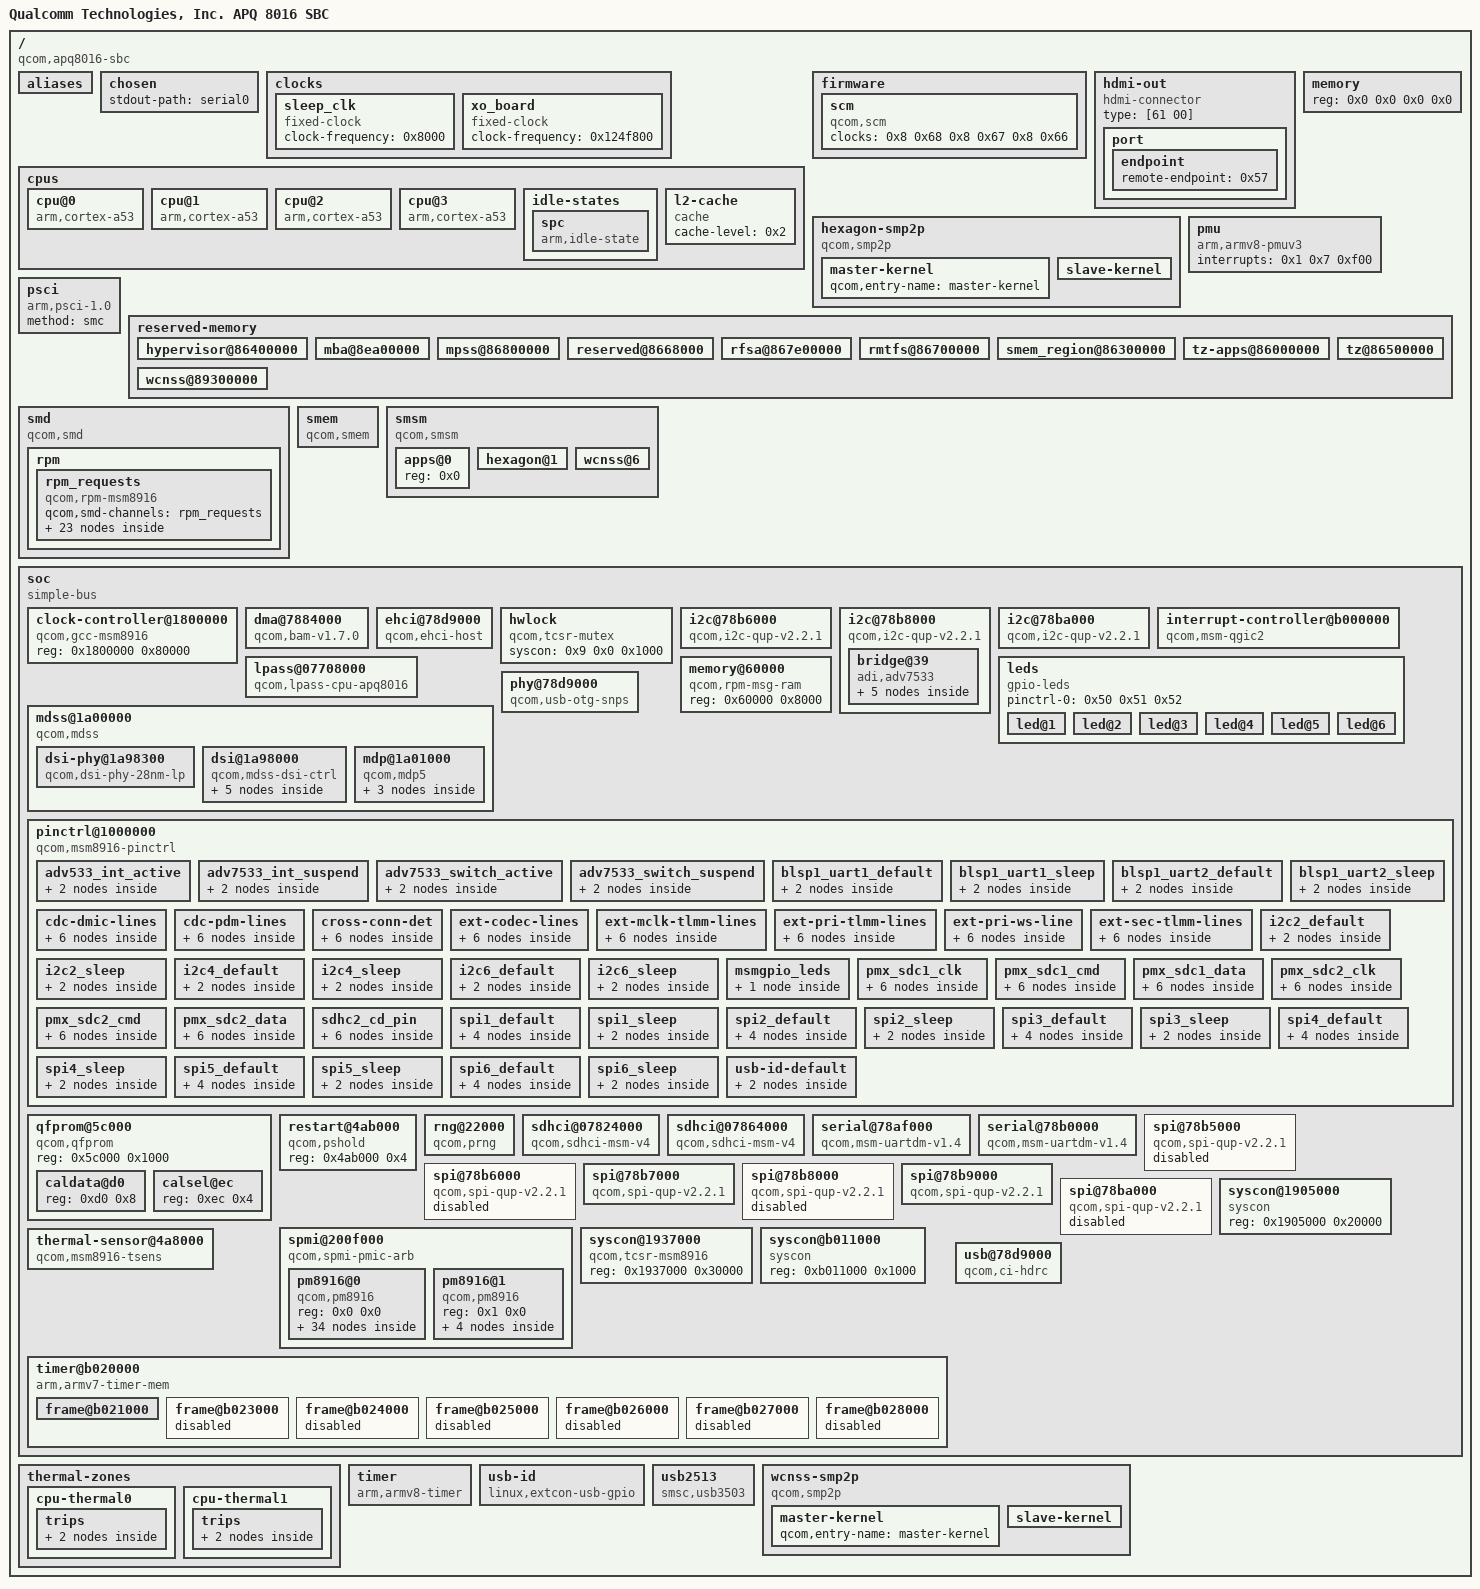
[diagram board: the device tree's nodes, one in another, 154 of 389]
/dts-v1/;

/ {
	#address-cells = <0x2>;
	#size-cells = <0x2>;
	compatible = "qcom,apq8016-sbc", "qcom,apq8016", "qcom,sbc";
	interrupt-parent = <0x1>;
	model = "Qualcomm Technologies, Inc. APQ 8016 SBC";

	__symbols__ {
		CPU0 = "/cpus/cpu@0";
		CPU1 = "/cpus/cpu@1";
		CPU2 = "/cpus/cpu@2";
		CPU3 = "/cpus/cpu@3";
		CPU_SPC = "/cpus/idle-states/spc";
		L2_0 = "/cpus/l2-cache";
		adv7533_in = "/soc/i2c@78b8000/bridge@39/ports/port@0/endpoint";
		adv7533_int_active = "/soc/pinctrl@1000000/adv533_int_active";
		adv7533_int_suspend = "/soc/pinctrl@1000000/adv7533_int_suspend";
		adv7533_out = "/soc/i2c@78b8000/bridge@39/ports/port@1/endpoint";
		adv7533_switch_active = "/soc/pinctrl@1000000/adv7533_switch_active";
		adv7533_switch_suspend = "/soc/pinctrl@1000000/adv7533_switch_suspend";
		adv_bridge = "/soc/i2c@78b8000/bridge@39";
		apcs = "/soc/syscon@b011000";
		apps_smsm = "/smsm/apps@0";
		blsp1_uart1 = "/soc/serial@78af000";
		blsp1_uart1_default = "/soc/pinctrl@1000000/blsp1_uart1_default";
		blsp1_uart1_sleep = "/soc/pinctrl@1000000/blsp1_uart1_sleep";
		blsp1_uart2 = "/soc/serial@78b0000";
		blsp1_uart2_default = "/soc/pinctrl@1000000/blsp1_uart2_default";
		blsp1_uart2_sleep = "/soc/pinctrl@1000000/blsp1_uart2_sleep";
		blsp_dma = "/soc/dma@7884000";
		blsp_i2c2 = "/soc/i2c@78b6000";
		blsp_i2c4 = "/soc/i2c@78b8000";
		blsp_i2c6 = "/soc/i2c@78ba000";
		blsp_spi1 = "/soc/spi@78b5000";
		blsp_spi2 = "/soc/spi@78b6000";
		blsp_spi3 = "/soc/spi@78b7000";
		blsp_spi4 = "/soc/spi@78b8000";
		blsp_spi5 = "/soc/spi@78b9000";
		blsp_spi6 = "/soc/spi@78ba000";
		cdc_dmic_lines_act = "/soc/pinctrl@1000000/cdc-dmic-lines/dmic_lines_on";
		cdc_dmic_lines_sus = "/soc/pinctrl@1000000/cdc-dmic-lines/dmic_lines_off";
		cdc_pdm_lines_act = "/soc/pinctrl@1000000/cdc-pdm-lines/pdm_lines_on";
		cdc_pdm_lines_sus = "/soc/pinctrl@1000000/cdc-pdm-lines/pdm_lines_off";
		cpu_alert0 = "/thermal-zones/cpu-thermal0/trips/trip0";
		cpu_alert1 = "/thermal-zones/cpu-thermal1/trips/trip0";
		cpu_crit0 = "/thermal-zones/cpu-thermal0/trips/trip1";
		cpu_crit1 = "/thermal-zones/cpu-thermal1/trips/trip1";
		cross_conn_det_act = "/soc/pinctrl@1000000/cross-conn-det/lines_on";
		cross_conn_det_sus = "/soc/pinctrl@1000000/cross-conn-det/lines_off";
		dsi0 = "/soc/mdss@1a00000/dsi@1a98000";
		dsi0_in = "/soc/mdss@1a00000/dsi@1a98000/ports/port@0/endpoint";
		dsi0_out = "/soc/mdss@1a00000/dsi@1a98000/ports/port@1/endpoint";
		dsi_phy0 = "/soc/mdss@1a00000/dsi-phy@1a98300";
		ext_codec_lines_act = "/soc/pinctrl@1000000/ext-codec-lines/lines_on";
		ext_codec_lines_sus = "/soc/pinctrl@1000000/ext-codec-lines/lines_off";
		ext_mclk_tlmm_lines_act = "/soc/pinctrl@1000000/ext-mclk-tlmm-lines/mclk_lines_on";
		ext_mclk_tlmm_lines_sus = "/soc/pinctrl@1000000/ext-mclk-tlmm-lines/mclk_lines_off";
		ext_pri_tlmm_lines_act = "/soc/pinctrl@1000000/ext-pri-tlmm-lines/ext_pa_on";
		ext_pri_tlmm_lines_sus = "/soc/pinctrl@1000000/ext-pri-tlmm-lines/ext_pa_off";
		ext_pri_ws_act = "/soc/pinctrl@1000000/ext-pri-ws-line/ext_pa_on";
		ext_pri_ws_sus = "/soc/pinctrl@1000000/ext-pri-ws-line/ext_pa_off";
		ext_sec_tlmm_lines_act = "/soc/pinctrl@1000000/ext-sec-tlmm-lines/tlmm_lines_on";
		ext_sec_tlmm_lines_sus = "/soc/pinctrl@1000000/ext-sec-tlmm-lines/tlmm_lines_off";
		gcc = "/soc/clock-controller@1800000";
		hdmi_con = "/hdmi-out/port/endpoint";
		hexagon_smp2p_in = "/hexagon-smp2p/slave-kernel";
		hexagon_smp2p_out = "/hexagon-smp2p/master-kernel";
		hexagon_smsm = "/smsm/hexagon@1";
		i2c2_default = "/soc/pinctrl@1000000/i2c2_default";
		i2c2_sleep = "/soc/pinctrl@1000000/i2c2_sleep";
		i2c4_default = "/soc/pinctrl@1000000/i2c4_default";
		i2c4_sleep = "/soc/pinctrl@1000000/i2c4_sleep";
		i2c6_default = "/soc/pinctrl@1000000/i2c6_default";
		i2c6_sleep = "/soc/pinctrl@1000000/i2c6_sleep";
		intc = "/soc/interrupt-controller@b000000";
		lpass = "/soc/lpass@07708000";
		mba_mem = "/reserved-memory/mba@8ea00000";
		mdp = "/soc/mdss@1a00000/mdp@1a01000";
		mdp5_intf1_out = "/soc/mdss@1a00000/mdp@1a01000/ports/port@0/endpoint";
		mdss = "/soc/mdss@1a00000";
		msmgpio = "/soc/pinctrl@1000000";
		msmgpio_leds = "/soc/pinctrl@1000000/msmgpio_leds";
		pm8916_0 = "/soc/spmi@200f000/pm8916@0";
		pm8916_1 = "/soc/spmi@200f000/pm8916@1";
		pm8916_adc_tm = "/soc/spmi@200f000/pm8916@0/vadc@3400";
		pm8916_bms = "/soc/spmi@200f000/pm8916@0/qcom,vmbms";
		pm8916_chg = "/soc/spmi@200f000/pm8916@0/qcom,charger";
		pm8916_coincell = "/soc/spmi@200f000/pm8916@0/qcom,coincell@2800";
		pm8916_gpios = "/soc/spmi@200f000/pm8916@0/pinctrl@c000";
		pm8916_gpios_leds = "/soc/spmi@200f000/pm8916@0/pinctrl@c000/pm8916_gpios_leds";
		pm8916_l1 = "/smd/rpm/rpm_requests/pm8916-regulators/l1";
		pm8916_l10 = "/smd/rpm/rpm_requests/pm8916-regulators/l10";
		pm8916_l11 = "/smd/rpm/rpm_requests/pm8916-regulators/l11";
		pm8916_l12 = "/smd/rpm/rpm_requests/pm8916-regulators/l12";
		pm8916_l13 = "/smd/rpm/rpm_requests/pm8916-regulators/l13";
		pm8916_l14 = "/smd/rpm/rpm_requests/pm8916-regulators/l14";
		pm8916_l15 = "/smd/rpm/rpm_requests/pm8916-regulators/l15";
		pm8916_l16 = "/smd/rpm/rpm_requests/pm8916-regulators/l16";
		pm8916_l17 = "/smd/rpm/rpm_requests/pm8916-regulators/l17";
		pm8916_l18 = "/smd/rpm/rpm_requests/pm8916-regulators/l18";
		pm8916_l2 = "/smd/rpm/rpm_requests/pm8916-regulators/l2";
		pm8916_l3 = "/smd/rpm/rpm_requests/pm8916-regulators/l3";
		pm8916_l4 = "/smd/rpm/rpm_requests/pm8916-regulators/l4";
		pm8916_l5 = "/smd/rpm/rpm_requests/pm8916-regulators/l5";
		pm8916_l6 = "/smd/rpm/rpm_requests/pm8916-regulators/l6";
		pm8916_l7 = "/smd/rpm/rpm_requests/pm8916-regulators/l7";
		pm8916_l8 = "/smd/rpm/rpm_requests/pm8916-regulators/l8";
		pm8916_l9 = "/smd/rpm/rpm_requests/pm8916-regulators/l9";
		pm8916_leds = "/soc/spmi@200f000/pm8916@0/qcom,leds@a100";
		pm8916_mpps = "/soc/spmi@200f000/pm8916@0/mpps@a000";
		pm8916_mpps_leds = "/soc/spmi@200f000/pm8916@0/mpps@a000/pm8916_mpps_leds";
		pm8916_pon = "/soc/spmi@200f000/pm8916@0/qcom,power-on@800";
		pm8916_pwm = "/soc/spmi@200f000/pm8916@1/qcom,pwms@bc00";
		pm8916_revid = "/soc/spmi@200f000/pm8916@0/qcom,revid@100";
		pm8916_rtc = "/soc/spmi@200f000/pm8916@0/qcom,pm8916_rtc";
		pm8916_s1 = "/smd/rpm/rpm_requests/pm8916-regulators/s1";
		pm8916_s3 = "/smd/rpm/rpm_requests/pm8916-regulators/s3";
		pm8916_s4 = "/smd/rpm/rpm_requests/pm8916-regulators/s4";
		pm8916_tombak_analog = "/soc/spmi@200f000/pm8916@1/msm8x16_wcd_codec@f100";
		pm8916_tombak_dig = "/soc/spmi@200f000/pm8916@1/msm8x16_wcd_codec@f000";
		pm8916_tz = "/soc/spmi@200f000/pm8916@0/qcom,temp-alarm@2400";
		pm8916_vadc = "/soc/spmi@200f000/pm8916@0/vadc@3100";
		pm8916_vib = "/soc/spmi@200f000/pm8916@1/qcom,vibrator@c000";
		qfprom = "/soc/qfprom@5c000";
		rpm_msg_ram = "/soc/memory@60000";
		rpmcc = "/smd/rpm/rpm_requests/qcom,rpmcc";
		scm = "/firmware/scm";
		sdc1_clk_off = "/soc/pinctrl@1000000/pmx_sdc1_clk/clk_off";
		sdc1_clk_on = "/soc/pinctrl@1000000/pmx_sdc1_clk/clk_on";
		sdc1_cmd_off = "/soc/pinctrl@1000000/pmx_sdc1_cmd/cmd_off";
		sdc1_cmd_on = "/soc/pinctrl@1000000/pmx_sdc1_cmd/cmd_on";
		sdc1_data_off = "/soc/pinctrl@1000000/pmx_sdc1_data/data_off";
		sdc1_data_on = "/soc/pinctrl@1000000/pmx_sdc1_data/data_on";
		sdc2_cd_off = "/soc/pinctrl@1000000/sdhc2_cd_pin/cd_off";
		sdc2_cd_on = "/soc/pinctrl@1000000/sdhc2_cd_pin/cd_on";
		sdc2_clk_off = "/soc/pinctrl@1000000/pmx_sdc2_clk/clk_off";
		sdc2_clk_on = "/soc/pinctrl@1000000/pmx_sdc2_clk/clk_on";
		sdc2_cmd_off = "/soc/pinctrl@1000000/pmx_sdc2_cmd/cmd_off";
		sdc2_cmd_on = "/soc/pinctrl@1000000/pmx_sdc2_cmd/cmd_on";
		sdc2_data_off = "/soc/pinctrl@1000000/pmx_sdc2_data/data_off";
		sdc2_data_on = "/soc/pinctrl@1000000/pmx_sdc2_data/data_on";
		sdhc_1 = "/soc/sdhci@07824000";
		sdhc_2 = "/soc/sdhci@07864000";
		sleep_clk = "/clocks/sleep_clk";
		smd_rpm_regulators = "/smd/rpm/rpm_requests/pm8916-regulators";
		smem_mem = "/reserved-memory/smem_region@86300000";
		soc = "/soc";
		spi1_default = "/soc/pinctrl@1000000/spi1_default";
		spi1_sleep = "/soc/pinctrl@1000000/spi1_sleep";
		spi2_default = "/soc/pinctrl@1000000/spi2_default";
		spi2_sleep = "/soc/pinctrl@1000000/spi2_sleep";
		spi3_default = "/soc/pinctrl@1000000/spi3_default";
		spi3_sleep = "/soc/pinctrl@1000000/spi3_sleep";
		spi4_default = "/soc/pinctrl@1000000/spi4_default";
		spi4_sleep = "/soc/pinctrl@1000000/spi4_sleep";
		spi5_default = "/soc/pinctrl@1000000/spi5_default";
		spi5_sleep = "/soc/pinctrl@1000000/spi5_sleep";
		spi6_default = "/soc/pinctrl@1000000/spi6_default";
		spi6_sleep = "/soc/pinctrl@1000000/spi6_sleep";
		spmi_bus = "/soc/spmi@200f000";
		tcsr = "/soc/syscon@1937000";
		tcsr_mutex = "/soc/hwlock";
		tcsr_mutex_regs = "/soc/syscon@1905000";
		tsens = "/soc/thermal-sensor@4a8000";
		tsens_caldata = "/soc/qfprom@5c000/caldata@d0";
		tsens_calsel = "/soc/qfprom@5c000/calsel@ec";
		usb_dev = "/soc/usb@78d9000";
		usb_host = "/soc/ehci@78d9000";
		usb_hub_reset_pm = "/soc/spmi@200f000/pm8916@0/pinctrl@c000/usb_hub_reset_pm";
		usb_id = "/usb-id";
		usb_id_default = "/soc/pinctrl@1000000/usb-id-default";
		usb_otg = "/soc/phy@78d9000";
		usb_sw_sel_pm = "/soc/spmi@200f000/pm8916@0/pinctrl@c000/usb_sw_sel_pm";
		wcnss_smp2p_in = "/wcnss-smp2p/slave-kernel";
		wcnss_smp2p_out = "/wcnss-smp2p/master-kernel";
		wcnss_smsm = "/smsm/wcnss@6";
		xo_board = "/clocks/xo_board";
	};

	aliases {
		i2c0 = "/soc/i2c@78b6000";
		i2c1 = "/soc/i2c@78ba000";
		i2c3 = "/soc/i2c@78b8000";
		sdhc1 = "/soc/sdhci@07824000";
		sdhc2 = "/soc/sdhci@07864000";
		serial0 = "/soc/serial@78b0000";
		serial1 = "/soc/serial@78af000";
		spi0 = "/soc/spi@78b9000";
		spi1 = "/soc/spi@78b7000";
		usid0 = "/soc/spmi@200f000/pm8916@0";
	};

	chosen {
		stdout-path = "serial0";
	};

	clocks {

		sleep_clk {
			#clock-cells = <0x0>;
			clock-frequency = <0x8000>;
			compatible = "fixed-clock";
			phandle = <0x62>;
		};

		xo_board {
			#clock-cells = <0x0>;
			clock-frequency = <0x124f800>;
			compatible = "fixed-clock";
			phandle = <0x61>;
		};
	};

	cpus {
		#address-cells = <0x1>;
		#size-cells = <0x0>;

		cpu@0 {
			compatible = "arm,cortex-a53", "arm,armv8";
			cpu-idle-states = <0x3>;
			device_type = "cpu";
			enable-method = "psci";
			next-level-cache = <0x2>;
			phandle = <0x59>;
			reg = <0x0>;
		};

		cpu@1 {
			compatible = "arm,cortex-a53", "arm,armv8";
			cpu-idle-states = <0x3>;
			device_type = "cpu";
			enable-method = "psci";
			next-level-cache = <0x2>;
			phandle = <0x5a>;
			reg = <0x1>;
		};

		cpu@2 {
			compatible = "arm,cortex-a53", "arm,armv8";
			cpu-idle-states = <0x3>;
			device_type = "cpu";
			enable-method = "psci";
			next-level-cache = <0x2>;
			phandle = <0x5b>;
			reg = <0x2>;
		};

		cpu@3 {
			compatible = "arm,cortex-a53", "arm,armv8";
			cpu-idle-states = <0x3>;
			device_type = "cpu";
			enable-method = "psci";
			next-level-cache = <0x2>;
			phandle = <0x5c>;
			reg = <0x3>;
		};

		idle-states {

			spc {
				arm,psci-suspend-param = <0x40000002>;
				compatible = "arm,idle-state";
				entry-latency-us = <0x82>;
				exit-latency-us = <0x96>;
				local-timer-stop;
				min-residency-us = <0x7d0>;
				phandle = <0x3>;
			};
		};

		l2-cache {
			cache-level = <0x2>;
			compatible = "cache";
			phandle = <0x2>;
		};
	};

	firmware {

		scm {
			#reset-cells = <0x1>;
			clock-names = "core", "bus", "iface";
			clocks = <0x8 0x68 0x8 0x67 0x8 0x66>;
			compatible = "qcom,scm";
			phandle = <0x63>;
		};
	};

	hdmi-out {
		compatible = "hdmi-connector";
		type = [61 00];

		port {

			endpoint {
				phandle = <0x27>;
				remote-endpoint = <0x57>;
			};
		};
	};

	hexagon-smp2p {
		compatible = "qcom,smp2p";
		interrupts = <0x0 0x1b 0x1>;
		qcom,ipc = <0x54 0x8 0xe>;
		qcom,local-pid = <0x0>;
		qcom,remote-pid = <0x1>;
		qcom,smem = <0x1b3 0x1ac>;

		master-kernel {
			#qcom,smem-state-cells = <0x1>;
			phandle = <0xa3>;
			qcom,entry-name = "master-kernel";
		};

		slave-kernel {
			#interrupt-cells = <0x2>;
			interrupt-controller;
			phandle = <0xa4>;
			qcom,entry-name = "slave-kernel";
		};
	};

	memory {
		device_type = "memory";
		reg = <0x0 0x0 0x0 0x0>;
	};

	pmu {
		compatible = "arm,armv8-pmuv3";
		interrupts = <0x1 0x7 0xf00>;
	};

	psci {
		compatible = "arm,psci-1.0";
		method = "smc";
	};

	reserved-memory {
		#address-cells = <0x2>;
		#size-cells = <0x2>;
		ranges;

		hypervisor@86400000 {
			no-map;
			reg = <0x0 0x86400000 0x0 0x100000>;
		};

		mba@8ea00000 {
			no-map;
			phandle = <0x58>;
			reg = <0x0 0x8ea00000 0x0 0x100000>;
		};

		mpss@86800000 {
			no-map;
			reg = <0x0 0x86800000 0x0 0x2b00000>;
		};

		reserved@8668000 {
			no-map;
			reg = <0x0 0x86680000 0x0 0x80000>;
		};

		rfsa@867e00000 {
			no-map;
			reg = <0x0 0x867e0000 0x0 0x20000>;
		};

		rmtfs@86700000 {
			no-map;
			reg = <0x0 0x86700000 0x0 0xe0000>;
		};

		smem_region@86300000 {
			no-map;
			phandle = <0x5>;
			reg = <0x0 0x86300000 0x0 0x100000>;
		};

		tz-apps@86000000 {
			no-map;
			reg = <0x0 0x86000000 0x0 0x300000>;
		};

		tz@86500000 {
			no-map;
			reg = <0x0 0x86500000 0x0 0x180000>;
		};

		wcnss@89300000 {
			no-map;
			reg = <0x0 0x89300000 0x0 0x600000>;
		};
	};

	smd {
		compatible = "qcom,smd";

		rpm {
			interrupts = <0x0 0xa8 0x1>;
			qcom,ipc = <0x54 0x8 0x0>;
			qcom,smd-edge = <0xf>;

			rpm_requests {
				compatible = "qcom,rpm-msm8916";
				qcom,smd-channels = "rpm_requests";

				pm8916-regulators {
					compatible = "qcom,rpm-pm8916-regulators";
					phandle = <0x99>;
					vdd_l1_l2_l3-supply = <0x55>;
					vdd_l4_l5_l6-supply = <0x47>;
					vdd_l5-supply = <0x55>;
					vdd_l7-supply = <0x47>;

					l1 {
						phandle = <0x9a>;
						regulator-max-microvolt = <0x174508>;
						regulator-min-microvolt = <0x5b8d8>;
					};

					l10 {
						phandle = <0x9e>;
						regulator-max-microvolt = <0x32eb28>;
						regulator-min-microvolt = <0x1ab3f0>;
					};

					l11 {
						phandle = <0x32>;
						regulator-max-microvolt = <0x32eb28>;
						regulator-min-microvolt = <0x1ab3f0>;
					};

					l12 {
						phandle = <0x33>;
						regulator-max-microvolt = <0x32eb28>;
						regulator-min-microvolt = <0x1ab3f0>;
					};

					l13 {
						phandle = <0x3f>;
						regulator-max-microvolt = <0x32eb28>;
						regulator-min-microvolt = <0x1ab3f0>;
					};

					l14 {
						phandle = <0x9f>;
						regulator-max-microvolt = <0x32eb28>;
						regulator-min-microvolt = <0x1ab3f0>;
					};

					l15 {
						phandle = <0xa0>;
						regulator-always-on;
						regulator-max-microvolt = <0x32eb28>;
						regulator-min-microvolt = <0x1ab3f0>;
					};

					l16 {
						phandle = <0xa1>;
						regulator-max-microvolt = <0x32eb28>;
						regulator-min-microvolt = <0x1ab3f0>;
					};

					l17 {
						phandle = <0x21>;
						regulator-max-microvolt = <0x32eb28>;
						regulator-min-microvolt = <0x1ab3f0>;
					};

					l18 {
						phandle = <0xa2>;
						regulator-max-microvolt = <0x32eb28>;
						regulator-min-microvolt = <0x1ab3f0>;
					};

					l2 {
						phandle = <0x4d>;
						regulator-max-microvolt = <0x174508>;
						regulator-min-microvolt = <0x5b8d8>;
					};

					l3 {
						phandle = <0x9b>;
						regulator-max-microvolt = <0x174508>;
						regulator-min-microvolt = <0x5b8d8>;
					};

					l4 {
						phandle = <0x9c>;
						regulator-max-microvolt = <0x32eb28>;
						regulator-min-microvolt = <0x1ab3f0>;
					};

					l5 {
						phandle = <0x2b>;
						regulator-max-microvolt = <0x32eb28>;
						regulator-min-microvolt = <0x1ab3f0>;
					};

					l6 {
						phandle = <0x20>;
						regulator-max-microvolt = <0x32eb28>;
						regulator-min-microvolt = <0x1ab3f0>;
					};

					l7 {
						phandle = <0x3e>;
						regulator-max-microvolt = <0x32eb28>;
						regulator-min-microvolt = <0x1ab3f0>;
					};

					l8 {
						phandle = <0x2a>;
						regulator-max-microvolt = <0x32eb28>;
						regulator-min-microvolt = <0x1ab3f0>;
					};

					l9 {
						phandle = <0x9d>;
						regulator-max-microvolt = <0x32eb28>;
						regulator-min-microvolt = <0x1ab3f0>;
					};

					s1 {
						phandle = <0x40>;
						regulator-max-microvolt = <0x17d590>;
						regulator-min-microvolt = <0x5b8d8>;
					};

					s3 {
						phandle = <0x55>;
						regulator-max-microvolt = <0x17d590>;
						regulator-min-microvolt = <0x5b8d8>;
					};

					s4 {
						phandle = <0x47>;
						regulator-always-on;
						regulator-boot-on;
						regulator-max-microvolt = <0x1b7740>;
						regulator-min-microvolt = <0x1b7740>;
					};
				};

				qcom,rpmcc {
					#clock-cells = <0x1>;
					compatible = "qcom,rpmcc-msm8916", "qcom,rpmcc";
					phandle = <0x98>;
				};
			};
		};
	};

	smem {
		compatible = "qcom,smem";
		hwlocks = <0x7 0x3>;
		memory-region = <0x5>;
		qcom,rpm-msg-ram = <0x6>;
	};

	smsm {
		#address-cells = <0x1>;
		#size-cells = <0x0>;
		compatible = "qcom,smsm";
		qcom,ipc-1 = <0x54 0x8 0xd>;
		qcom,ipc-3 = <0x54 0x8 0x13>;

		apps@0 {
			#qcom,smem-state-cells = <0x1>;
			phandle = <0xa7>;
			reg = <0x0>;
		};

		hexagon@1 {
			#interrupt-cells = <0x2>;
			interrupt-controller;
			interrupts = <0x0 0x1a 0x1>;
			phandle = <0xa8>;
			reg = <0x1>;
		};

		wcnss@6 {
			#interrupt-cells = <0x2>;
			interrupt-controller;
			interrupts = <0x0 0x90 0x1>;
			phandle = <0xa9>;
			reg = <0x6>;
		};
	};

	soc {
		#address-cells = <0x1>;
		#size-cells = <0x1>;
		compatible = "simple-bus";
		phandle = <0x64>;
		ranges = <0x0 0x0 0x0 0xffffffff>;

		clock-controller@1800000 {
			#clock-cells = <0x1>;
			#power-domain-cells = <0x1>;
			#reset-cells = <0x1>;
			compatible = "qcom,gcc-msm8916";
			phandle = <0x8>;
			reg = <0x1800000 0x80000>;
		};

		dma@7884000 {
			#dma-cells = <0x1>;
			clock-names = "bam_clk";
			clocks = <0x8 0x36>;
			compatible = "qcom,bam-v1.7.0";
			interrupts = <0x0 0xee 0x4>;
			phandle = <0xa>;
			qcom,ee = <0x0>;
			reg = <0x7884000 0x23000>;
			status = "okay";
		};

		ehci@78d9000 {
			compatible = "qcom,ehci-host";
			interrupts = <0x0 0x86 0x4>;
			phandle = <0x86>;
			reg = <0x78d9000 0x400>;
			status = "okay";
			usb-phy = <0x3c>;
		};

		hwlock {
			#hwlock-cells = <0x1>;
			compatible = "qcom,tcsr-mutex";
			phandle = <0x7>;
			syscon = <0x9 0x0 0x1000>;
		};

		i2c@78b6000 {
			#address-cells = <0x1>;
			#size-cells = <0x0>;
			clock-names = "iface", "core";
			clocks = <0x8 0x36 0x8 0x3a>;
			compatible = "qcom,i2c-qup-v2.2.1";
			interrupts = <0x0 0x60 0x0>;
			label = "LS-I2C0";
			phandle = <0x7e>;
			pinctrl-0 = <0x1b>;
			pinctrl-1 = <0x1c>;
			pinctrl-names = "default", "sleep";
			reg = <0x78b6000 0x1000>;
			status = "okay";
		};

		i2c@78b8000 {
			#address-cells = <0x1>;
			#size-cells = <0x0>;
			clock-names = "iface", "core";
			clocks = <0x8 0x36 0x8 0x3e>;
			compatible = "qcom,i2c-qup-v2.2.1";
			interrupts = <0x0 0x62 0x0>;
			label = "HS-I2C2";
			phandle = <0x7f>;
			pinctrl-0 = <0x1d>;
			pinctrl-1 = <0x1e>;
			pinctrl-names = "default", "sleep";
			reg = <0x78b8000 0x1000>;
			status = "okay";

			bridge@39 {
				adi,dsi-lanes = <0x4>;
				avdd-supply = <0x20>;
				compatible = "adi,adv7533";
				interrupt-parent = <0x1f>;
				interrupts = <0x1f 0x2>;
				pd-gpios = <0x1f 0x20 0x0>;
				phandle = <0x80>;
				pinctrl-0 = <0x22 0x23>;
				pinctrl-1 = <0x24 0x25>;
				pinctrl-names = "default", "sleep";
				reg = <0x39>;
				status = "okay";
				v1p2-supply = <0x20>;
				v3p3-supply = <0x21>;

				ports {
					#address-cells = <0x1>;
					#size-cells = <0x0>;

					port@0 {
						reg = <0x0>;

						endpoint {
							phandle = <0x4f>;
							remote-endpoint = <0x26>;
						};
					};

					port@1 {
						reg = <0x1>;

						endpoint {
							phandle = <0x57>;
							remote-endpoint = <0x27>;
						};
					};
				};
			};
		};

		i2c@78ba000 {
			#address-cells = <0x1>;
			#size-cells = <0x0>;
			clock-names = "iface", "core";
			clocks = <0x8 0x36 0x8 0x42>;
			compatible = "qcom,i2c-qup-v2.2.1";
			interrupts = <0x0 0x64 0x0>;
			label = "LS-I2C1";
			phandle = <0x81>;
			pinctrl-0 = <0x28>;
			pinctrl-1 = <0x29>;
			pinctrl-names = "default", "sleep";
			reg = <0x78ba000 0x1000>;
			status = "okay";
		};

		interrupt-controller@b000000 {
			#interrupt-cells = <0x3>;
			compatible = "qcom,msm-qgic2";
			interrupt-controller;
			phandle = <0x1>;
			reg = <0xb000000 0x1000 0xb002000 0x1000>;
		};

		leds {
			compatible = "gpio-leds";
			pinctrl-0 = <0x50 0x51 0x52>;
			pinctrl-names = "default";

			led@1 {
				default-state = "off";
				gpios = <0x1f 0x15 0x0>;
				label = "apq8016-sbc:green:user1";
				linux,default-trigger = "heartbeat";
			};

			led@2 {
				default-state = "off";
				gpios = <0x1f 0x78 0x0>;
				label = "apq8016-sbc:green:user2";
				linux,default-trigger = "mmc0";
			};

			led@3 {
				default-state = "off";
				gpios = <0x41 0x1 0x0>;
				label = "apq8016-sbc:green:user3";
				linux,default-trigger = "mmc1";
			};

			led@4 {
				default-state = "off";
				gpios = <0x41 0x2 0x0>;
				label = "apq8016-sbc:green:user4";
				linux,default-trigger = "none";
			};

			led@5 {
				default-state = "off";
				gpios = <0x53 0x2 0x0>;
				label = "apq8016-sbc:yellow:wlan";
				linux,default-trigger = "wlan";
			};

			led@6 {
				default-state = "off";
				gpios = <0x53 0x3 0x0>;
				label = "apq8016-sbc:blue:bt";
				linux,default-trigger = "bluetooth-power";
			};
		};

		lpass@07708000 {
			#sound-dai-cells = <0x1>;
			clock-names = "ahbix-clk", "pcnoc-mport-clk", "pcnoc-sway-clk", "mi2s-bit-clk0", "mi2s-bit-clk1", "mi2s-bit-clk2", "mi2s-bit-clk3";
			clocks = <0x8 0x9a 0x8 0x96 0x8 0x97 0x8 0x9c 0x8 0x9d 0x8 0x9d 0x8 0x9e>;
			compatible = "qcom,lpass-cpu-apq8016";
			interrupt-names = "lpass-irq-lpaif";
			interrupts = <0x0 0xa0 0x0>;
			phandle = <0x82>;
			reg = <0x7708000 0x10000>;
			reg-names = "lpass-lpaif";
			status = "okay";
		};

		mdss@1a00000 {
			#address-cells = <0x1>;
			#interrupt-cells = <0x1>;
			#size-cells = <0x1>;
			clock-names = "iface_clk", "bus_clk", "vsync_clk";
			clocks = <0x8 0x6d 0x8 0x6e 0x8 0x73>;
			compatible = "qcom,mdss";
			interrupt-controller;
			interrupts = <0x0 0x48 0x0>;
			phandle = <0x4a>;
			power-domains = <0x8 0x2>;
			ranges;
			reg = <0x1a00000 0x1000 0x1ac8000 0x3000>;
			reg-names = "mdss_phys", "vbif_phys";
			status = "okay";

			dsi-phy@1a98300 {
				#clock-cells = <0x1>;
				#phy-cells = <0x0>;
				clock-names = "iface_clk";
				clocks = <0x8 0x6d>;
				compatible = "qcom,dsi-phy-28nm-lp";
				phandle = <0x4c>;
				reg = <0x1a98300 0xd4 0x1a98500 0x280 0x1a98780 0x30>;
				reg-names = "dsi_pll", "dsi_phy", "dsi_phy_regulator";
				status = "okay";
				vddio-supply = <0x20>;
			};

			dsi@1a98000 {
				assigned-clock-parents = <0x4c 0x0 0x4c 0x1>;
				assigned-clocks = <0x8 0x2b 0x8 0x2e>;
				clock-names = "mdp_core_clk", "iface_clk", "bus_clk", "byte_clk", "pixel_clk", "core_clk";
				clocks = <0x8 0x71 0x8 0x6d 0x8 0x6e 0x8 0x6f 0x8 0x72 0x8 0x70>;
				compatible = "qcom,mdss-dsi-ctrl";
				interrupt-parent = <0x4a>;
				interrupts = <0x4 0x0>;
				phandle = <0x97>;
				phy-names = "dsi-phy";
				phys = <0x4c>;
				reg = <0x1a98000 0x25c>;
				reg-names = "dsi_ctrl";
				status = "okay";
				vdda-supply = <0x4d>;
				vddio-supply = <0x20>;

				ports {
					#address-cells = <0x1>;
					#size-cells = <0x0>;

					port@0 {
						reg = <0x0>;

						endpoint {
							phandle = <0x4b>;
							remote-endpoint = <0x4e>;
						};
					};

					port@1 {
						reg = <0x1>;

						endpoint {
							data-lanes = <0x0 0x1 0x2 0x3>;
							phandle = <0x26>;
							remote-endpoint = <0x4f>;
						};
					};
				};
			};

			mdp@1a01000 {
				clock-names = "iface_clk", "bus_clk", "core_clk", "vsync_clk";
				clocks = <0x8 0x6d 0x8 0x6e 0x8 0x71 0x8 0x73>;
				compatible = "qcom,mdp5";
				interrupt-parent = <0x4a>;
				interrupts = <0x0 0x0>;
				phandle = <0x96>;
				reg = <0x1a01000 0x90000>;
				reg-names = "mdp_phys";
				status = "okay";

				ports {
					#address-cells = <0x1>;
					#size-cells = <0x0>;

					port@0 {
						reg = <0x0>;

						endpoint {
							phandle = <0x4e>;
							remote-endpoint = <0x4b>;
						};
					};
				};
			};
		};

		memory@60000 {
			compatible = "qcom,rpm-msg-ram";
			phandle = <0x6>;
			reg = <0x60000 0x8000>;
		};

		phy@78d9000 {
			clock-names = "iface", "core", "sleep";
			clocks = <0x8 0x85 0x8 0x86 0x8 0x84>;
			compatible = "qcom,usb-otg-snps";
			dr_mode = "otg";
			extcon = <0x3d 0x3d>;
			interrupts = <0x0 0x86 0x4 0x0 0x8c 0x4>;
			phandle = <0x3c>;
			pinctrl-0 = <0x42>;
			pinctrl-names = "default";
			qcom,manual-pullup;
			qcom,otg-control = <0x2>;
			qcom,phy-init-sequence = <0x44 0x6b 0x24 0x13>;
			qcom,vdd-levels = <0x7a120 0xf4240 0x142440>;
			reg = <0x78d9000 0x400>;
			reset-names = "phy", "link";
			resets = <0x8 0x23 0x8 0x22>;
			status = "okay";
			switch-gpio = <0x41 0x4 0x0>;
			v1p8-supply = <0x3e>;
			v3p3-supply = <0x3f>;
			vddcx-supply = <0x40>;
		};

		pinctrl@1000000 {
			#gpio-cells = <0x2>;
			#interrupt-cells = <0x2>;
			compatible = "qcom,msm8916-pinctrl";
			gpio-controller;
			interrupt-controller;
			interrupts = <0x0 0xd0 0x4>;
			phandle = <0x1f>;
			reg = <0x1000000 0x300000>;

			adv533_int_active {
				phandle = <0x22>;

				pinconf {
					bias-disable;
					drive-strength = <0x10>;
					pins = "gpio31";
				};

				pinmux {
					function = "gpio";
					pins = "gpio31";
				};
			};

			adv7533_int_suspend {
				phandle = <0x24>;

				pinconf {
					bias-disable;
					drive-strength = <0x2>;
					pins = "gpio31";
				};

				pinmux {
					function = "gpio";
					pins = "gpio31";
				};
			};

			adv7533_switch_active {
				phandle = <0x23>;

				pinconf {
					bias-disable;
					drive-strength = <0x10>;
					pins = "gpio32";
				};

				pinmux {
					function = "gpio";
					pins = "gpio32";
				};
			};

			adv7533_switch_suspend {
				phandle = <0x25>;

				pinconf {
					bias-disable;
					drive-strength = <0x2>;
					pins = "gpio32";
				};

				pinmux {
					function = "gpio";
					pins = "gpio32";
				};
			};

			blsp1_uart1_default {
				phandle = <0xb>;

				pinconf {
					bias-disable;
					drive-strength = <0x10>;
					pins = "gpio0", "gpio1", "gpio2", "gpio3";
				};

				pinmux {
					function = "blsp_uart1";
					pins = "gpio0", "gpio1", "gpio2", "gpio3";
				};
			};

			blsp1_uart1_sleep {
				phandle = <0xc>;

				pinconf {
					bias-pull-down;
					drive-strength = <0x2>;
					pins = "gpio0", "gpio1", "gpio2", "gpio3";
				};

				pinmux {
					function = "gpio";
					pins = "gpio0", "gpio1", "gpio2", "gpio3";
				};
			};

			blsp1_uart2_default {
				phandle = <0xd>;

				pinconf {
					bias-disable;
					drive-strength = <0x10>;
					pins = "gpio4", "gpio5";
				};

				pinmux {
					function = "blsp_uart2";
					pins = "gpio4", "gpio5";
				};
			};

			blsp1_uart2_sleep {
				phandle = <0xe>;

				pinconf {
					bias-pull-down;
					drive-strength = <0x2>;
					pins = "gpio4", "gpio5";
				};

				pinmux {
					function = "gpio";
					pins = "gpio4", "gpio5";
				};
			};

			cdc-dmic-lines {

				dmic_lines_off {
					phandle = <0x72>;

					pinconf {
						bias-disable;
						drive-strength = <0x2>;
						pins = "gpio0", "gpio1";
					};
				};

				dmic_lines_on {
					phandle = <0x71>;

					pinconf {
						drive-strength = <0x8>;
						pins = "gpio0", "gpio1";
					};

					pinmux_dmic0_clk {
						function = "dmic0_clk";
						pins = "gpio0";
					};

					pinmux_dmic0_data {
						function = "dmic0_data";
						pins = "gpio1";
					};
				};
			};

			cdc-pdm-lines {

				pdm_lines_off {
					phandle = <0x68>;

					pinconf {
						bias-disable;
						drive-strength = <0x2>;
						pins = "gpio63", "gpio64", "gpio65", "gpio66", "gpio67", "gpio68";
					};

					pinmux {
						function = "cdc_pdm0";
						pins = "gpio63", "gpio64", "gpio65", "gpio66", "gpio67", "gpio68";
					};
				};

				pdm_lines_on {
					phandle = <0x67>;

					pinconf {
						bias-pull-none;
						drive-strength = <0x8>;
						pins = "gpio63", "gpio64", "gpio65", "gpio66", "gpio67", "gpio68";
					};

					pinmux {
						function = "cdc_pdm0";
						pins = "gpio63", "gpio64", "gpio65", "gpio66", "gpio67", "gpio68";
					};
				};
			};

			cross-conn-det {

				lines_off {
					phandle = <0x74>;

					pinconf {
						bias-disable;
						drive-strength = <0x2>;
						pins = "gpio120";
					};

					pinmux {
						function = "gpio";
						pins = "gpio120";
					};
				};

				lines_on {
					phandle = <0x73>;

					pinconf {
						bias-pull-down;
						drive-strength = <0x8>;
						output-low;
						pins = "gpio120";
					};

					pinmux {
						function = "gpio";
						pins = "gpio120";
					};
				};
			};

			ext-codec-lines {

				lines_off {
					phandle = <0x66>;

					pinconf {
						bias-disable;
						drive-strength = <0x2>;
						pins = "gpio67";
					};

					pinmux {
						function = "gpio";
						pins = "gpio67";
					};
				};

				lines_on {
					phandle = <0x65>;

					pinconf {
						bias-disable;
						drive-strength = <0x8>;
						output-high;
						pins = "gpio67";
					};

					pinmux {
						function = "gpio";
						pins = "gpio67";
					};
				};
			};

			ext-mclk-tlmm-lines {

				mclk_lines_off {
					phandle = <0x6e>;

					pinconf {
						bias-disable;
						drive-strength = <0x2>;
						pins = "gpio116";
					};

					pinmux {
						function = "pri_mi2s";
						pins = "gpio116";
					};
				};

				mclk_lines_on {
					phandle = <0x6d>;

					pinconf {
						bias-pull-none;
						drive-strength = <0x8>;
						pins = "gpio116";
					};

					pinmux {
						function = "pri_mi2s";
						pins = "gpio116";
					};
				};
			};

			ext-pri-tlmm-lines {

				ext_pa_off {
					phandle = <0x6a>;

					pinconf {
						bias-disable;
						drive-strength = <0x2>;
						pins = "gpio113", "gpio114", "gpio115", "gpio116";
					};

					pinmux {
						function = "pri_mi2s";
						pins = "gpio113", "gpio114", "gpio115", "gpio116";
					};
				};

				ext_pa_on {
					phandle = <0x69>;

					pinconf {
						bias-pull-none;
						drive-strength = <0x8>;
						pins = "gpio113", "gpio114", "gpio115", "gpio116";
					};

					pinmux {
						function = "pri_mi2s";
						pins = "gpio113", "gpio114", "gpio115", "gpio116";
					};
				};
			};

			ext-pri-ws-line {

				ext_pa_off {
					phandle = <0x6c>;

					pinconf {
						bias-disable;
						drive-strength = <0x2>;
						pins = "gpio110";
					};

					pinmux {
						function = "pri_mi2s_ws";
						pins = "gpio110";
					};
				};

				ext_pa_on {
					phandle = <0x6b>;

					pinconf {
						bias-pull-none;
						drive-strength = <0x8>;
						pins = "gpio110";
					};

					pinmux {
						function = "pri_mi2s_ws";
						pins = "gpio110";
					};
				};
			};

			ext-sec-tlmm-lines {

				tlmm_lines_off {
					phandle = <0x70>;

					pinconf {
						bias-disable;
						drive-strength = <0x2>;
						pins = "gpio112", "gpio117", "gpio118", "gpio119";
					};

					pinmux {
						function = "sec_mi2s";
						pins = "gpio112", "gpio117", "gpio118", "gpio119";
					};
				};

				tlmm_lines_on {
					phandle = <0x6f>;

					pinconf {
						bias-pull-none;
						drive-strength = <0x8>;
						pins = "gpio112", "gpio117", "gpio118", "gpio119";
					};

					pinmux {
						function = "sec_mi2s";
						pins = "gpio112", "gpio117", "gpio118", "gpio119";
					};
				};
			};

			i2c2_default {
				phandle = <0x1b>;

				pinconf {
					bias-disable = <0x0>;
					drive-strength = <0x10>;
					pins = "gpio6", "gpio7";
				};

				pinmux {
					function = "blsp_i2c2";
					pins = "gpio6", "gpio7";
				};
			};

			i2c2_sleep {
				phandle = <0x1c>;

				pinconf {
					bias-disable = <0x0>;
					drive-strength = <0x2>;
					pins = "gpio6", "gpio7";
				};

				pinmux {
					function = "gpio";
					pins = "gpio6", "gpio7";
				};
			};

			i2c4_default {
				phandle = <0x1d>;

				pinconf {
					bias-disable = <0x0>;
					drive-strength = <0x10>;
					pins = "gpio14", "gpio15";
				};

				pinmux {
					function = "blsp_i2c4";
					pins = "gpio14", "gpio15";
				};
			};

			i2c4_sleep {
				phandle = <0x1e>;

				pinconf {
					bias-disable = <0x0>;
					drive-strength = <0x2>;
					pins = "gpio14", "gpio15";
				};

				pinmux {
					function = "gpio";
					pins = "gpio14", "gpio15";
				};
			};

			i2c6_default {
				phandle = <0x28>;

				pinconf {
					bias-disable = <0x0>;
					drive-strength = <0x10>;
					pins = "gpio22", "gpio23";
				};

				pinmux {
					function = "blsp_i2c6";
					pins = "gpio22", "gpio23";
				};
			};

			i2c6_sleep {
				phandle = <0x29>;

				pinconf {
					bias-disable = <0x0>;
					drive-strength = <0x2>;
					pins = "gpio22", "gpio23";
				};

				pinmux {
					function = "gpio";
					pins = "gpio22", "gpio23";
				};
			};

			msmgpio_leds {
				phandle = <0x50>;

				pinconf {
					function = "gpio";
					output-low;
					pins = "gpio21", "gpio120";
				};
			};

			pmx_sdc1_clk {

				clk_off {
					phandle = <0x2f>;

					pinconf {
						bias-disable;
						drive-strength = <0x2>;
						pins = "sdc1_clk";
					};

					pinmux {
						pins = "sdc1_clk";
					};
				};

				clk_on {
					phandle = <0x2c>;

					pinconf {
						bias-disable;
						drive-strength = <0x10>;
						pins = "sdc1_clk";
					};

					pinmux {
						pins = "sdc1_clk";
					};
				};
			};

			pmx_sdc1_cmd {

				cmd_off {
					phandle = <0x30>;

					pinconf {
						bias-pull-up;
						drive-strength = <0x2>;
						pins = "sdc1_cmd";
					};

					pinmux {
						pins = "sdc1_cmd";
					};
				};

				cmd_on {
					phandle = <0x2d>;

					pinconf {
						bias-pull-up;
						drive-strength = <0xa>;
						pins = "sdc1_cmd";
					};

					pinmux {
						pins = "sdc1_cmd";
					};
				};
			};

			pmx_sdc1_data {

				data_off {
					phandle = <0x31>;

					pinconf {
						bias-pull-up;
						drive-strength = <0x2>;
						pins = "sdc1_data";
					};

					pinmux {
						pins = "sdc1_data";
					};
				};

				data_on {
					phandle = <0x2e>;

					pinconf {
						bias-pull-up;
						drive-strength = <0xa>;
						pins = "sdc1_data";
					};

					pinmux {
						pins = "sdc1_data";
					};
				};
			};

			pmx_sdc2_clk {

				clk_off {
					phandle = <0x38>;

					pinconf {
						bias-disable;
						drive-strength = <0x2>;
						pins = "sdc2_clk";
					};

					pinmux {
						pins = "sdc2_clk";
					};
				};

				clk_on {
					phandle = <0x34>;

					pinconf {
						bias-disable;
						drive-strength = <0x10>;
						pins = "sdc2_clk";
					};

					pinmux {
						pins = "sdc2_clk";
					};
				};
			};

			pmx_sdc2_cmd {

				cmd_off {
					phandle = <0x39>;

					pinconf {
						bias-pull-up;
						drive-strength = <0x2>;
						pins = "sdc2_cmd";
					};

					pinmux {
						pins = "sdc2_cmd";
					};
				};

				cmd_on {
					phandle = <0x35>;

					pinconf {
						bias-pull-up;
						drive-strength = <0xa>;
						pins = "sdc2_cmd";
					};

					pinmux {
						pins = "sdc2_cmd";
					};
				};
			};

			pmx_sdc2_data {

				data_off {
					phandle = <0x3a>;

					pinconf {
						bias-pull-up;
						drive-strength = <0x2>;
						pins = "sdc2_data";
					};

					pinmux {
						pins = "sdc2_data";
					};
				};

				data_on {
					phandle = <0x36>;

					pinconf {
						bias-pull-up;
						drive-strength = <0xa>;
						pins = "sdc2_data";
					};

					pinmux {
						pins = "sdc2_data";
					};
				};
			};

			sdhc2_cd_pin {

				cd_off {
					phandle = <0x3b>;

					pinconf {
						bias-disable;
						drive-strength = <0x2>;
						pins = "gpio38";
					};

					pinmux {
						function = "gpio";
						pins = "gpio38";
					};
				};

				cd_on {
					phandle = <0x37>;

					pinconf {
						bias-pull-up;
						drive-strength = <0x2>;
						pins = "gpio38";
					};

					pinmux {
						function = "gpio";
						pins = "gpio38";
					};
				};
			};

			spi1_default {
				phandle = <0xf>;

				pinconf {
					bias-disable;
					drive-strength = <0xc>;
					pins = "gpio0", "gpio1", "gpio3";
				};

				pinconf_cs {
					bias-disable;
					drive-strength = <0x10>;
					output-high;
					pins = "gpio2";
				};

				pinmux {
					function = "blsp_spi1";
					pins = "gpio0", "gpio1", "gpio3";
				};

				pinmux_cs {
					function = "gpio";
					pins = "gpio2";
				};
			};

			spi1_sleep {
				phandle = <0x10>;

				pinconf {
					bias-pull-down;
					drive-strength = <0x2>;
					pins = "gpio0", "gpio1", "gpio2", "gpio3";
				};

				pinmux {
					function = "gpio";
					pins = "gpio0", "gpio1", "gpio2", "gpio3";
				};
			};

			spi2_default {
				phandle = <0x11>;

				pinconf {
					bias-disable;
					drive-strength = <0xc>;
					pins = "gpio4", "gpio5", "gpio7";
				};

				pinconf_cs {
					bias-disable;
					drive-strength = <0x10>;
					output-high;
					pins = "gpio6";
				};

				pinmux {
					function = "blsp_spi2";
					pins = "gpio4", "gpio5", "gpio7";
				};

				pinmux_cs {
					function = "gpio";
					pins = "gpio6";
				};
			};

			spi2_sleep {
				phandle = <0x12>;

				pinconf {
					bias-pull-down;
					drive-strength = <0x2>;
					pins = "gpio4", "gpio5", "gpio6", "gpio7";
				};

				pinmux {
					function = "gpio";
					pins = "gpio4", "gpio5", "gpio6", "gpio7";
				};
			};

			spi3_default {
				phandle = <0x13>;

				pinconf {
					bias-disable;
					drive-strength = <0xc>;
					pins = "gpio8", "gpio9", "gpio11";
				};

				pinconf_cs {
					bias-disable;
					drive-strength = <0x10>;
					output-high;
					pins = "gpio10";
				};

				pinmux {
					function = "blsp_spi3";
					pins = "gpio8", "gpio9", "gpio11";
				};

				pinmux_cs {
					function = "gpio";
					pins = "gpio10";
				};
			};

			spi3_sleep {
				phandle = <0x14>;

				pinconf {
					bias-pull-down;
					drive-strength = <0x2>;
					pins = "gpio8", "gpio9", "gpio10", "gpio11";
				};

				pinmux {
					function = "gpio";
					pins = "gpio8", "gpio9", "gpio10", "gpio11";
				};
			};

			spi4_default {
				phandle = <0x15>;

				pinconf {
					bias-disable;
					drive-strength = <0xc>;
					pins = "gpio12", "gpio13", "gpio15";
				};

				pinconf_cs {
					bias-disable;
					drive-strength = <0x10>;
					output-high;
					pins = "gpio14";
				};

				pinmux {
					function = "blsp_spi4";
					pins = "gpio12", "gpio13", "gpio15";
				};

				pinmux_cs {
					function = "gpio";
					pins = "gpio14";
				};
			};

			spi4_sleep {
				phandle = <0x16>;

				pinconf {
					bias-pull-down;
					drive-strength = <0x2>;
					pins = "gpio12", "gpio13", "gpio14", "gpio15";
				};

				pinmux {
					function = "gpio";
					pins = "gpio12", "gpio13", "gpio14", "gpio15";
				};
			};

			spi5_default {
				phandle = <0x17>;

				pinconf {
					bias-disable;
					drive-strength = <0xc>;
					pins = "gpio16", "gpio17", "gpio19";
				};

				pinconf_cs {
					bias-disable;
					drive-strength = <0x10>;
					output-high;
					pins = "gpio18";
				};

				pinmux {
					function = "blsp_spi5";
					pins = "gpio16", "gpio17", "gpio19";
				};

				pinmux_cs {
					function = "gpio";
					pins = "gpio18";
				};
			};

			spi5_sleep {
				phandle = <0x18>;

				pinconf {
					bias-pull-down;
					drive-strength = <0x2>;
					pins = "gpio16", "gpio17", "gpio18", "gpio19";
				};

				pinmux {
					function = "gpio";
					pins = "gpio16", "gpio17", "gpio18", "gpio19";
				};
			};

			spi6_default {
				phandle = <0x19>;

				pinconf {
					bias-disable;
					drive-strength = <0xc>;
					pins = "gpio20", "gpio21", "gpio23";
				};

				pinconf_cs {
					bias-disable;
					drive-strength = <0x10>;
					output-high;
					pins = "gpio22";
				};

				pinmux {
					function = "blsp_spi6";
					pins = "gpio20", "gpio21", "gpio23";
				};

				pinmux_cs {
					function = "gpio";
					pins = "gpio22";
				};
			};

			spi6_sleep {
				phandle = <0x1a>;

				pinconf {
					bias-pull-down;
					drive-strength = <0x2>;
					pins = "gpio20", "gpio21", "gpio22", "gpio23";
				};

				pinmux {
					function = "gpio";
					pins = "gpio20", "gpio21", "gpio22", "gpio23";
				};
			};

			usb-id-default {
				phandle = <0x56>;

				pinconf {
					bias-pull-up;
					drive-strength = <0x8>;
					input-enable;
					pins = "gpio121";
				};

				pinmux {
					function = "gpio";
					pins = "gpio121";
				};
			};
		};

		qfprom@5c000 {
			#address-cells = <0x1>;
			#size-cells = <0x1>;
			compatible = "qcom,qfprom";
			phandle = <0x95>;
			reg = <0x5c000 0x1000>;

			caldata@d0 {
				phandle = <0x48>;
				reg = <0xd0 0x8>;
			};

			calsel@ec {
				phandle = <0x49>;
				reg = <0xec 0x4>;
			};
		};

		restart@4ab000 {
			compatible = "qcom,pshold";
			reg = <0x4ab000 0x4>;
		};

		rng@22000 {
			clock-names = "core";
			clocks = <0x8 0x79>;
			compatible = "qcom,prng";
			reg = <0x22000 0x200>;
		};

		sdhci@07824000 {
			bus-width = <0x8>;
			clock-names = "core", "iface";
			clocks = <0x8 0x7b 0x8 0x7a>;
			compatible = "qcom,sdhci-msm-v4";
			interrupt-names = "hc_irq", "pwr_irq";
			interrupts = <0x0 0x7b 0x0 0x0 0x8a 0x0>;
			non-removable;
			phandle = <0x83>;
			pinctrl-0 = <0x2c 0x2d 0x2e>;
			pinctrl-1 = <0x2f 0x30 0x31>;
			pinctrl-names = "default", "sleep";
			reg = <0x7824900 0x11c 0x7824000 0x800>;
			reg-names = "hc_mem", "core_mem";
			status = "okay";
			vmmc-supply = <0x2a>;
			vqmmc-supply = <0x2b>;
		};

		sdhci@07864000 {
			bus-width = <0x4>;
			cd-gpios = <0x1f 0x26 0x1>;
			clock-names = "core", "iface";
			clocks = <0x8 0x7d 0x8 0x7c>;
			compatible = "qcom,sdhci-msm-v4";
			interrupt-names = "hc_irq", "pwr_irq";
			interrupts = <0x0 0x7d 0x0 0x0 0xdd 0x0>;
			phandle = <0x84>;
			pinctrl-0 = <0x34 0x35 0x36 0x37>;
			pinctrl-1 = <0x38 0x39 0x3a 0x3b>;
			pinctrl-names = "default", "sleep";
			reg = <0x7864900 0x11c 0x7864000 0x800>;
			reg-names = "hc_mem", "core_mem";
			status = "okay";
			vmmc-supply = <0x32>;
			vqmmc-supply = <0x33>;
		};

		serial@78af000 {
			clock-names = "core", "iface";
			clocks = <0x8 0x44 0x8 0x36>;
			compatible = "qcom,msm-uartdm-v1.4", "qcom,msm-uartdm";
			dma-names = "rx", "tx";
			dmas = <0xa 0x1 0xa 0x0>;
			interrupts = <0x0 0x6b 0x4>;
			label = "LS-UART0";
			phandle = <0x76>;
			pinctrl-0 = <0xb>;
			pinctrl-1 = <0xc>;
			pinctrl-names = "default", "sleep";
			reg = <0x78af000 0x200>;
			status = "okay";
		};

		serial@78b0000 {
			clock-names = "core", "iface";
			clocks = <0x8 0x45 0x8 0x36>;
			compatible = "qcom,msm-uartdm-v1.4", "qcom,msm-uartdm";
			dma-names = "rx", "tx";
			dmas = <0xa 0x3 0xa 0x2>;
			interrupts = <0x0 0x6c 0x4>;
			label = "LS-UART1";
			phandle = <0x77>;
			pinctrl-0 = <0xd>;
			pinctrl-1 = <0xe>;
			pinctrl-names = "default", "sleep";
			reg = <0x78b0000 0x200>;
			status = "okay";
		};

		spi@78b5000 {
			#address-cells = <0x1>;
			#size-cells = <0x0>;
			clock-names = "core", "iface";
			clocks = <0x8 0x39 0x8 0x36>;
			compatible = "qcom,spi-qup-v2.2.1";
			dma-names = "rx", "tx";
			dmas = <0xa 0x5 0xa 0x4>;
			interrupts = <0x0 0x5f 0x4>;
			phandle = <0x78>;
			pinctrl-0 = <0xf>;
			pinctrl-1 = <0x10>;
			pinctrl-names = "default", "sleep";
			reg = <0x78b5000 0x600>;
			status = "disabled";
		};

		spi@78b6000 {
			#address-cells = <0x1>;
			#size-cells = <0x0>;
			clock-names = "core", "iface";
			clocks = <0x8 0x3b 0x8 0x36>;
			compatible = "qcom,spi-qup-v2.2.1";
			dma-names = "rx", "tx";
			dmas = <0xa 0x7 0xa 0x6>;
			interrupts = <0x0 0x60 0x4>;
			phandle = <0x79>;
			pinctrl-0 = <0x11>;
			pinctrl-1 = <0x12>;
			pinctrl-names = "default", "sleep";
			reg = <0x78b6000 0x600>;
			status = "disabled";
		};

		spi@78b7000 {
			#address-cells = <0x1>;
			#size-cells = <0x0>;
			clock-names = "core", "iface";
			clocks = <0x8 0x3d 0x8 0x36>;
			compatible = "qcom,spi-qup-v2.2.1";
			dma-names = "rx", "tx";
			dmas = <0xa 0x9 0xa 0x8>;
			interrupts = <0x0 0x61 0x4>;
			label = "HS-SPI1";
			phandle = <0x7a>;
			pinctrl-0 = <0x13>;
			pinctrl-1 = <0x14>;
			pinctrl-names = "default", "sleep";
			reg = <0x78b7000 0x600>;
			status = "okay";
		};

		spi@78b8000 {
			#address-cells = <0x1>;
			#size-cells = <0x0>;
			clock-names = "core", "iface";
			clocks = <0x8 0x3f 0x8 0x36>;
			compatible = "qcom,spi-qup-v2.2.1";
			dma-names = "rx", "tx";
			dmas = <0xa 0xb 0xa 0xa>;
			interrupts = <0x0 0x62 0x4>;
			phandle = <0x7b>;
			pinctrl-0 = <0x15>;
			pinctrl-1 = <0x16>;
			pinctrl-names = "default", "sleep";
			reg = <0x78b8000 0x600>;
			status = "disabled";
		};

		spi@78b9000 {
			#address-cells = <0x1>;
			#size-cells = <0x0>;
			clock-names = "core", "iface";
			clocks = <0x8 0x41 0x8 0x36>;
			compatible = "qcom,spi-qup-v2.2.1";
			dma-names = "rx", "tx";
			dmas = <0xa 0xd 0xa 0xc>;
			interrupts = <0x0 0x63 0x4>;
			label = "LS-SPI0";
			phandle = <0x7c>;
			pinctrl-0 = <0x17>;
			pinctrl-1 = <0x18>;
			pinctrl-names = "default", "sleep";
			reg = <0x78b9000 0x600>;
			status = "okay";
		};

		spi@78ba000 {
			#address-cells = <0x1>;
			#size-cells = <0x0>;
			clock-names = "core", "iface";
			clocks = <0x8 0x43 0x8 0x36>;
			compatible = "qcom,spi-qup-v2.2.1";
			dma-names = "rx", "tx";
			dmas = <0xa 0xf 0xa 0xe>;
			interrupts = <0x0 0x64 0x4>;
			phandle = <0x7d>;
			pinctrl-0 = <0x19>;
			pinctrl-1 = <0x1a>;
			pinctrl-names = "default", "sleep";
			reg = <0x78ba000 0x600>;
			status = "disabled";
		};

		spmi@200f000 {
			#address-cells = <0x2>;
			#interrupt-cells = <0x4>;
			#size-cells = <0x0>;
			compatible = "qcom,spmi-pmic-arb";
			interrupt-controller;
			interrupt-names = "periph_irq";
			interrupts = <0x0 0xbe 0x4>;
			phandle = <0x46>;
			qcom,channel = <0x0>;
			qcom,ee = <0x0>;
			reg = <0x200f000 0x1000 0x2400000 0x400000 0x2c00000 0x400000 0x3800000 0x200000 0x200a000 0x2100>;
			reg-names = "core", "chnls", "obsrvr", "intr", "cnfg";

			pm8916@0 {
				#address-cells = <0x1>;
				#size-cells = <0x1>;
				compatible = "qcom,pm8916", "qcom,spmi-pmic";
				phandle = <0x87>;
				reg = <0x0 0x0>;

				mpps@a000 {
					#gpio-cells = <0x2>;
					compatible = "qcom,pm8916-mpp";
					gpio-controller;
					interrupt-names = "pm8916_mpp1", "pm8916_mpp2", "pm8916_mpp3", "pm8916_mpp4";
					interrupts = <0x0 0xa0 0x0 0x0 0x0 0xa1 0x0 0x0 0x0 0xa2 0x0 0x0 0x0 0xa3 0x0 0x0>;
					phandle = <0x53>;
					reg = <0xa000 0x400>;

					pm8916_mpps_leds {
						phandle = <0x52>;

						pinconf {
							function = "digital";
							output-low;
							pins = "mpp2", "mpp3";
						};
					};
				};

				pinctrl@c000 {
					#gpio-cells = <0x2>;
					compatible = "qcom,pm8916-gpio";
					gpio-controller;
					interrupt-names = "pm8916_gpio1", "pm8916_gpio2", "pm8916_gpio3", "pm8916_gpio4";
					interrupts = <0x0 0xc0 0x0 0x0 0x0 0xc1 0x0 0x0 0x0 0xc2 0x0 0x0 0x0 0xc3 0x0 0x0>;
					phandle = <0x41>;
					reg = <0xc000 0x400>;

					pm8916_gpios_leds {
						phandle = <0x51>;

						pinconf {
							function = "normal";
							output-low;
							pins = "gpio1", "gpio2";
						};
					};

					usb_hub_reset_pm {
						phandle = <0x89>;

						pinconf {
							function = "normal";
							output-low;
							pins = "gpio3";
						};
					};

					usb_sw_sel_pm {
						phandle = <0x42>;

						pinconf {
							function = "normal";
							input-disable;
							pins = "gpio4";
							power-source = <0x0>;
						};
					};
				};

				qcom,charger {
					#address-cells = <0x1>;
					#size-cells = <0x1>;
					compatible = "qcom,qpnp-linear-charger";
					phandle = <0x8d>;
					qcom,batt-cold-percentage = <0x50>;
					qcom,batt-hot-percentage = <0x19>;
					qcom,chg-adc_tm = <0x45>;
					qcom,chg-vadc = <0x44>;
					qcom,cool-bat-decidegc = <0x64>;
					qcom,cool-bat-mv = <0x1004>;
					qcom,ibatmax-cool-ma = <0x168>;
					qcom,ibatmax-warm-ma = <0x168>;
					qcom,ibatsafe-ma = <0x5a0>;
					qcom,resume-soc = <0x63>;
					qcom,tchg-mins = <0xe8>;
					qcom,thermal-mitigation = <0x5a0 0x2d0 0x276 0x0>;
					qcom,vddmax-mv = <0x1068>;
					qcom,vddsafe-mv = <0x1068>;
					qcom,vinmin-mv = <0x10d4>;
					qcom,warm-bat-decidegc = <0x1c2>;
					qcom,warm-bat-mv = <0x1004>;
					status = "disabled";

					qcom,bat-if@1200 {
						interrupt-names = "bat-temp-ok", "batt-pres";
						interrupts = <0x0 0x12 0x1 0x3 0x0 0x12 0x0 0x3>;
						reg = <0x1200 0x100>;
					};

					qcom,chg-misc@1600 {
						reg = <0x1600 0x100>;
					};

					qcom,chgr@1000 {
						interrupt-names = "chg-done", "chg-failed", "fast-chg-on", "vbat-det-lo";
						interrupts = <0x0 0x10 0x7 0x1 0x0 0x10 0x6 0x1 0x0 0x10 0x5 0x3 0x0 0x10 0x0 0x2>;
						reg = <0x1000 0x100>;
					};

					qcom,usb-chgpth@1300 {
						interrupt-names = "usb-over-temp", "chg-gone", "usbin-valid";
						interrupts = <0x0 0x13 0x4 0x3 0x0 0x13 0x2 0x1 0x0 0x13 0x1 0x3>;
						reg = <0x1300 0x100>;
					};
				};

				qcom,coincell@2800 {
					compatible = "qcom,qpnp-coincell";
					phandle = <0x8a>;
					reg = <0x2800 0x100>;
				};

				qcom,leds@a100 {
					compatible = "qcom,leds-qpnp";
					label = "mpp";
					phandle = <0x8f>;
					reg = <0xa100 0x100>;
				};

				qcom,pm8916_rtc {
					#address-cells = <0x1>;
					#size-cells = <0x1>;
					compatible = "qcom,qpnp-rtc";
					phandle = <0x8b>;
					qcom,qpnp-rtc-alarm-pwrup = <0x0>;
					qcom,qpnp-rtc-write = <0x0>;

					qcom,pm8916_rtc_alarm@6100 {
						interrupts = <0x0 0x61 0x1 0x0>;
						reg = <0x6100 0x100>;
					};

					qcom,pm8916_rtc_rw@6000 {
						reg = <0x6000 0x100>;
					};
				};

				qcom,power-on@800 {
					compatible = "qcom,qpnp-power-on";
					interrupt-names = "kpdpwr", "resin";
					interrupts = <0x0 0x8 0x0 0x0 0x0 0x8 0x1 0x0>;
					phandle = <0x88>;
					qcom,clear-warm-reset;
					qcom,pon-dbc-delay = <0x3d09>;
					qcom,store-hard-reset-reason;
					qcom,system-reset;
					reg = <0x800 0x100>;

					qcom,pon_1 {
						linux,code = <0x74>;
						qcom,pon-type = <0x0>;
						qcom,pull-up = <0x1>;
						qcom,s1-timer = <0x2810>;
						qcom,s2-timer = <0x7d0>;
						qcom,s2-type = <0x1>;
						qcom,support-reset = <0x1>;
					};

					qcom,pon_2 {
						linux,code = <0x72>;
						qcom,pon-type = <0x1>;
						qcom,pull-up = <0x1>;
					};
				};

				qcom,revid@100 {
					compatible = "qcom,qpnp-revid";
					phandle = <0x43>;
					reg = <0x100 0x100>;
				};

				qcom,temp-alarm@2400 {
					#thermal-sensor-cells = <0x0>;
					compatible = "qcom,qpnp-temp-alarm";
					interrupts = <0x0 0x24 0x0 0x1>;
					label = "pm8916_tz";
					phandle = <0x8c>;
					qcom,channel-num = <0x8>;
					qcom,temp_alarm-vadc = <0x44>;
					qcom,threshold-set = <0x0>;
					reg = <0x2400 0x100>;
				};

				qcom,vmbms {
					#address-cells = <0x1>;
					#size-cells = <0x1>;
					compatible = "qcom,qpnp-vm-bms";
					phandle = <0x8e>;
					qcom,bms-adc_tm = <0x45>;
					qcom,bms-vadc = <0x44>;
					qcom,calculate-soc-ms = <0x4e20>;
					qcom,force-s2-in-charging;
					qcom,force-s3-on-suspend;
					qcom,low-soc-calculate-soc-ms = <0x1388>;
					qcom,low-soc-calculate-soc-threshold = <0xf>;
					qcom,low-soc-fifo-length = <0x2>;
					qcom,low-voltage-calculate-soc-ms = <0x3e8>;
					qcom,low-voltage-threshold = <0x34a490>;
					qcom,max-voltage-uv = <0x401640>;
					qcom,pmic-revid = <0x43>;
					qcom,r-conn-mohm = <0x0>;
					qcom,report-charger-eoc;
					qcom,s2-fifo-length = <0x5>;
					qcom,s3-ocv-tolerence-uv = <0x4b0>;
					qcom,shutdown-soc-valid-limit = <0x64>;
					qcom,v-cutoff-uv = <0x33e140>;
					qcom,volatge-soc-timeout-ms = <0xea60>;
					status = "disabled";

					qcom,batt-pres-status@1208 {
						reg = <0x1208 0x1>;
					};

					qcom,qpnp-chg-pres@1008 {
						reg = <0x1008 0x1>;
					};

					qcom,vm-bms@4000 {
						interrupt-names = "leave_cv", "enter_cv", "good_ocv", "ocv_thr", "fifo_update_done", "fsm_state_change";
						interrupts = <0x0 0x40 0x0 0x0 0x0 0x40 0x1 0x0 0x0 0x40 0x2 0x0 0x0 0x40 0x3 0x0 0x0 0x40 0x4 0x0 0x0 0x40 0x5 0x0>;
						reg = <0x4000 0x100>;
					};
				};

				vadc@3100 {
					#address-cells = <0x1>;
					#size-cells = <0x0>;
					#thermal-sensor-cells = <0x1>;
					compatible = "qcom,qpnp-vadc";
					interrupt-names = "eoc-int-en-set";
					interrupts = <0x0 0x31 0x0 0x1>;
					phandle = <0x44>;
					qcom,adc-bit-resolution = <0xf>;
					qcom,adc-vdd-reference = <0x708>;
					qcom,pmic-revid = <0x43>;
					qcom,vadc-poll-eoc;
					reg = <0x3100 0x100>;

					chan@8 {
						label = "die_temp";
						qcom,calibration-type = "absolute";
						qcom,decimation = <0x0>;
						qcom,fast-avg-setup = <0x0>;
						qcom,hw-settle-time = <0x0>;
						qcom,pre-div-channel-scaling = <0x0>;
						qcom,scale-function = <0x3>;
						reg = <0x8>;
					};

					chan@9 {
						label = "ref_625mv";
						qcom,calibration-type = "absolute";
						qcom,decimation = <0x0>;
						qcom,fast-avg-setup = <0x0>;
						qcom,hw-settle-time = <0x0>;
						qcom,pre-div-channel-scaling = <0x0>;
						qcom,scale-function = <0x0>;
						reg = <0x9>;
					};

					chan@a {
						label = "ref_1250v";
						qcom,calibration-type = "absolute";
						qcom,decimation = <0x0>;
						qcom,fast-avg-setup = <0x0>;
						qcom,hw-settle-time = <0x0>;
						qcom,pre-div-channel-scaling = <0x0>;
						qcom,scale-function = <0x0>;
						reg = <0xa>;
					};
				};

				vadc@3400 {
					#address-cells = <0x1>;
					#size-cells = <0x0>;
					compatible = "qcom,qpnp-adc-tm";
					interrupt-names = "eoc-int-en-set", "high-thr-en-set", "low-thr-en-set";
					interrupts = <0x0 0x34 0x0 0x1 0x0 0x34 0x3 0x1 0x0 0x34 0x4 0x1>;
					phandle = <0x45>;
					qcom,adc-bit-resolution = <0xf>;
					qcom,adc-vdd-reference = <0x708>;
					qcom,adc_tm-vadc = <0x44>;
					qcom,pmic-revid = <0x43>;
					reg = <0x3400 0x100>;
				};
			};

			pm8916@1 {
				#address-cells = <0x1>;
				#size-cells = <0x1>;
				compatible = "qcom,pm8916", "qcom,spmi-pmic";
				phandle = <0x90>;
				reg = <0x1 0x0>;

				msm8x16_wcd_codec@f000 {
					cdc-vdd-mic-bias-supply = <0x3f>;
					cdc-vdd-pa-supply = <0x2b>;
					cdc-vdd-px-supply = <0x47>;
					cdc-vdda-cp-supply = <0x47>;
					cdc-vdda-h-supply = <0x2b>;
					compatible = "qcom,msm8x16_wcd_codec";
					interrupt-names = "spk_cnp_int", "spk_clip_int", "spk_ocp_int", "ins_rem_det1", "but_rel_det", "but_press_det", "ins_rem_det", "mbhc_int";
					interrupt-parent = <0x46>;
					interrupts = <0x1 0xf0 0x0 0x0 0x1 0xf0 0x1 0x0 0x1 0xf0 0x2 0x0 0x1 0xf0 0x3 0x0 0x1 0xf0 0x4 0x0 0x1 0xf0 0x5 0x0 0x1 0xf0 0x6 0x0 0x1 0xf0 0x7 0x0>;
					phandle = <0x93>;
					qcom,cdc-mclk-clk-rate = <0x927c00>;
					qcom,cdc-on-demand-supplies = "cdc-vdd-mic-bias";
					qcom,cdc-static-supplies = "cdc-vdda-h", "cdc-vdd-px", "cdc-vdd-pa", "cdc-vdda-cp";
					qcom,cdc-vdd-mic-bias-current = <0x61a8>;
					qcom,cdc-vdd-mic-bias-voltage = <0x2eebb8 0x2eebb8>;
					qcom,cdc-vdd-pa-current = <0x1388>;
					qcom,cdc-vdd-pa-voltage = <0x1b7740 0x1b7740>;
					qcom,cdc-vdd-px-current = <0xbbfd0>;
					qcom,cdc-vdd-px-voltage = <0x1b7740 0x2191c0>;
					qcom,cdc-vdda-cp-current = <0xbbfd0>;
					qcom,cdc-vdda-cp-voltage = <0x1b7740 0x2191c0>;
					qcom,cdc-vdda-h-current = <0x4e20>;
					qcom,cdc-vdda-h-voltage = <0x1b7740 0x1b7740>;
					qcom,subsys-name = "modem";
					reg = <0xf000 0x100>;
				};

				msm8x16_wcd_codec@f100 {
					compatible = "qcom,msm8x16_wcd_codec";
					interrupt-names = "ear_ocp_int", "hphr_ocp_int", "hphl_ocp_det", "ear_cnp_int", "hphr_cnp_int", "hphl_cnp_int";
					interrupt-parent = <0x46>;
					interrupts = <0x1 0xf1 0x0 0x0 0x1 0xf1 0x1 0x0 0x1 0xf1 0x2 0x0 0x1 0xf1 0x3 0x0 0x1 0xf1 0x4 0x0 0x1 0xf1 0x5 0x0>;
					phandle = <0x94>;
					reg = <0xf100 0x100>;
				};

				qcom,pwms@bc00 {
					#pwm-cells = <0x2>;
					compatible = "qcom,pwm-lpg";
					phandle = <0x91>;
					reg = <0xbc00 0x100>;
					reg-names = "lpg-base";
				};

				qcom,vibrator@c000 {
					compatible = "qcom,qpnp-vibrator";
					label = "vibrator";
					phandle = <0x92>;
					reg = <0xc000 0x100>;
					status = "disabled";
				};
			};
		};

		syscon@1905000 {
			compatible = "syscon";
			phandle = <0x9>;
			reg = <0x1905000 0x20000>;
		};

		syscon@1937000 {
			compatible = "qcom,tcsr-msm8916", "syscon";
			phandle = <0x75>;
			reg = <0x1937000 0x30000>;
		};

		syscon@b011000 {
			compatible = "syscon";
			phandle = <0x54>;
			reg = <0xb011000 0x1000>;
		};

		thermal-sensor@4a8000 {
			#thermal-sensor-cells = <0x1>;
			compatible = "qcom,msm8916-tsens";
			nvmem-cell-names = "calib", "calib_sel";
			nvmem-cells = <0x48 0x49>;
			phandle = <0x4>;
			reg = <0x4a8000 0x2000>;
		};

		timer@b020000 {
			#address-cells = <0x1>;
			#size-cells = <0x1>;
			clock-frequency = <0x124f800>;
			compatible = "arm,armv7-timer-mem";
			ranges;
			reg = <0xb020000 0x1000>;

			frame@b021000 {
				frame-number = <0x0>;
				interrupts = <0x0 0x8 0x4 0x0 0x7 0x4>;
				reg = <0xb021000 0x1000 0xb022000 0x1000>;
			};

			frame@b023000 {
				frame-number = <0x1>;
				interrupts = <0x0 0x9 0x4>;
				reg = <0xb023000 0x1000>;
				status = "disabled";
			};

			frame@b024000 {
				frame-number = <0x2>;
				interrupts = <0x0 0xa 0x4>;
				reg = <0xb024000 0x1000>;
				status = "disabled";
			};

			frame@b025000 {
				frame-number = <0x3>;
				interrupts = <0x0 0xb 0x4>;
				reg = <0xb025000 0x1000>;
				status = "disabled";
			};

			frame@b026000 {
				frame-number = <0x4>;
				interrupts = <0x0 0xc 0x4>;
				reg = <0xb026000 0x1000>;
				status = "disabled";
			};

			frame@b027000 {
				frame-number = <0x5>;
				interrupts = <0x0 0xd 0x4>;
				reg = <0xb027000 0x1000>;
				status = "disabled";
			};

			frame@b028000 {
				frame-number = <0x6>;
				interrupts = <0x0 0xe 0x4>;
				reg = <0xb028000 0x1000>;
				status = "disabled";
			};
		};

		usb@78d9000 {
			compatible = "qcom,ci-hdrc";
			dr_mode = "peripheral";
			extcon = <0x3d 0x3d>;
			interrupts = <0x0 0x86 0x4>;
			phandle = <0x85>;
			reg = <0x78d9000 0x400>;
			status = "okay";
			usb-phy = <0x3c>;
		};
	};

	thermal-zones {

		cpu-thermal0 {
			polling-delay = <0x3e8>;
			polling-delay-passive = <0xfa>;
			thermal-sensors = <0x4 0x4>;

			trips {

				trip0 {
					hysteresis = <0x7d0>;
					phandle = <0x5d>;
					temperature = <0x124f8>;
					type = "passive";
				};

				trip1 {
					hysteresis = <0x7d0>;
					phandle = <0x5e>;
					temperature = <0x1adb0>;
					type = "critical";
				};
			};
		};

		cpu-thermal1 {
			polling-delay = <0x3e8>;
			polling-delay-passive = <0xfa>;
			thermal-sensors = <0x4 0x3>;

			trips {

				trip0 {
					hysteresis = <0x7d0>;
					phandle = <0x5f>;
					temperature = <0x124f8>;
					type = "passive";
				};

				trip1 {
					hysteresis = <0x7d0>;
					phandle = <0x60>;
					temperature = <0x1adb0>;
					type = "critical";
				};
			};
		};
	};

	timer {
		compatible = "arm,armv8-timer";
		interrupts = <0x1 0x2 0xf08 0x1 0x3 0xf08 0x1 0x4 0xf08 0x1 0x1 0xf08>;
	};

	usb-id {
		compatible = "linux,extcon-usb-gpio";
		id-gpio = <0x1f 0x79 0x0>;
		phandle = <0x3d>;
		pinctrl-0 = <0x56>;
		pinctrl-names = "default";
	};

	usb2513 {
		compatible = "smsc,usb3503";
		initial-mode = <0x1>;
		reset-gpios = <0x41 0x3 0x1>;
	};

	wcnss-smp2p {
		compatible = "qcom,smp2p";
		interrupts = <0x0 0x8f 0x1>;
		qcom,ipc = <0x54 0x8 0x12>;
		qcom,local-pid = <0x0>;
		qcom,remote-pid = <0x4>;
		qcom,smem = <0x1c3 0x1af>;

		master-kernel {
			#qcom,smem-state-cells = <0x1>;
			phandle = <0xa5>;
			qcom,entry-name = "master-kernel";
		};

		slave-kernel {
			#interrupt-cells = <0x2>;
			interrupt-controller;
			phandle = <0xa6>;
			qcom,entry-name = "slave-kernel";
		};
	};
};
